# MCU_CTRL_MMR0_CFG0 register map
Vendor: Texas Instruments
Peripheral module from a debugger description file (folder am65x).
Registers are 32-bit, access per field, reset 0x0 unless marked. A register's access mark holds for its fields unless they carry their own. Offsets are as the file gives them; lines under a group give offsets from that group; [hi:lo] are bit positions; {n}, {i} and the like mark numbered series; 'fields as' and 'values as' point back to an identical list; <NAME> marks a mode.

## MCU_CTRL_MMR0_CFG0
0x00 CTRLMMR_MCU_PID ro reset 0x61800212 — Peripheral release details.
  [31:0] REV — TI internal data.
0x08 CTRLMMR_MCU_MMR_CFG1 ro reset 0x8000001F — Indicates the MMR configuration.
  [7:0] PARTITIONS — Indicates present partitions
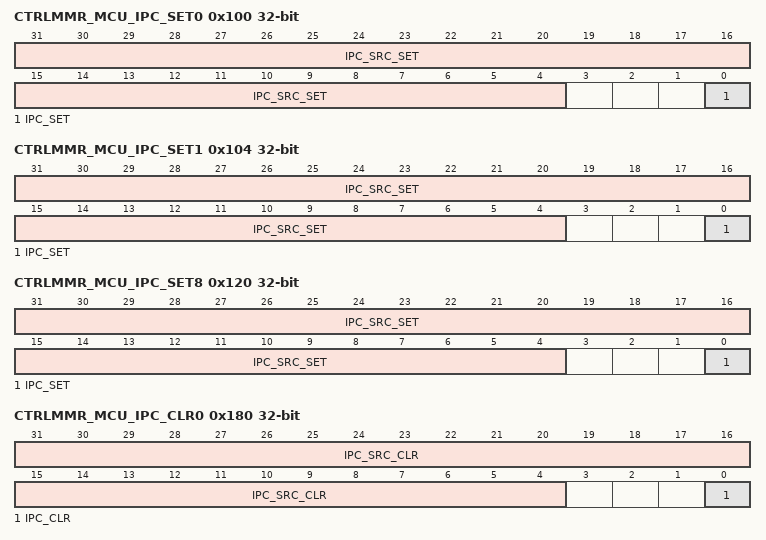
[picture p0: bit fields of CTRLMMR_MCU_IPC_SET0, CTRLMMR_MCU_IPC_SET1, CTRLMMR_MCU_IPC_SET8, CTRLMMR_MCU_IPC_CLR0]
0x100 CTRLMMR_MCU_IPC_SET0 access not given — Generate interprocessor communication interrupt to MCU R5 core0.
  [31:4] IPC_SRC_SET — Read returns current value (access W1TS)
  [0] IPC_SET — Read returns 0 (access W1TS)
0x104 CTRLMMR_MCU_IPC_SET1 access not given — Generate interprocessor communication interrupt to MCU R5 core1.
  fields as CTRLMMR_MCU_IPC_SET0
0x120 CTRLMMR_MCU_IPC_SET8 access not given — Generate interprocessor communication interrupt to DMSC.
  fields as CTRLMMR_MCU_IPC_SET0
0x180 CTRLMMR_MCU_IPC_CLR0 access not given — Acknowledge interprocessor communication interrupt to MCU R5 core0.
  [31:4] IPC_SRC_CLR — Read returns current value (access W1TC)
  [0] IPC_CLR — Read returns current value (access W1TC)
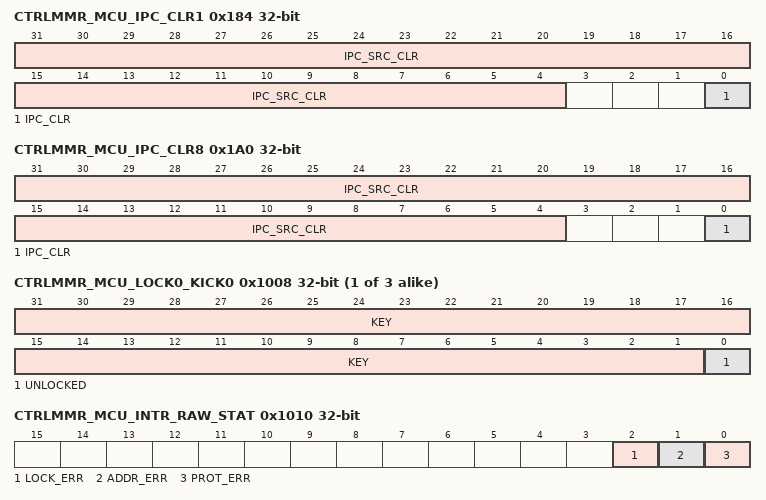
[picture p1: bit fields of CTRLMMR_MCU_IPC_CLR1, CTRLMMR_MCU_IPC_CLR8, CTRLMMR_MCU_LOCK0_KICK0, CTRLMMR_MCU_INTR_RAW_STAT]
0x184 CTRLMMR_MCU_IPC_CLR1 access not given — Acknowledge interprocessor communication interrupt to MCU R5 core1.
  fields as CTRLMMR_MCU_IPC_CLR0
0x1A0 CTRLMMR_MCU_IPC_CLR8 access not given — Acknowledge interprocessor communication interrupt to DMSC.
  fields as CTRLMMR_MCU_IPC_CLR0
0x200 CTRLMMR_MCU_MAC_ID0 ro reset not defined — MCU Ethernet MAC address lower 32-bits.
  [31:0] MACID_LO — 32 lsbs of MAC address
0x204 CTRLMMR_MCU_MAC_ID1 ro (reset mask 0xFFFF0000) — MCU Ethernet MAC address upper 16-bits.
  [15:0] MACID_HI — 16 msbs of MAC address
{0x1008+0x4000*i} CTRLMMR_MCU_LOCK{i}_KICK0 (i=0..2) — Lower 32-bits of Partition{i} write lock key. This register must be written with the designated key value followed by a write to CTRLMMR_MCU_LOCK{i}_KICK1 with its key value before write-protected Partition {i} registers can be written.
  [31:1] KEY rw — Write the kick0 unlock value followed by the kick1 unlock value to unlock the write-protected Partition{i} registers
  [0] UNLOCKED ro — Unlock status. When set indicates that the proper umlock sequence has been performed and the partition is unlocked for writing.
{0x100C+0x4000*i} CTRLMMR_MCU_LOCK{i}_KICK1 rw (i=0..2) — Upper 32-bits of Partition {i} write lock key. This register must be written with the designated key value after a write to CTRLMMR_MCU_LOCK{i}_KICK0 with its key value before write-protected Partition {i} registers can be written.
  [31:0] KEY — Write the kick1 unlock value after the kick0 unlock value to unlock the write-protected Partition{i} registers
0x1010 CTRLMMR_MCU_INTR_RAW_STAT access not given — Shows the interupt status (before enabling) and allows setting of the interrupt status (for test).
  [2] LOCK_ERR — Lock violation occurred (attempt to write a write-locked register with partition locked) (access W1TS)
  [1] ADDR_ERR — Address violation occurred (attempt to read or write an invalid register address) (access W1TS)
  [0] PROT_ERR — Protection violation occurred (attempt to to read or write a register with insufficient sucurity or privilege access rights) (access W1TS)
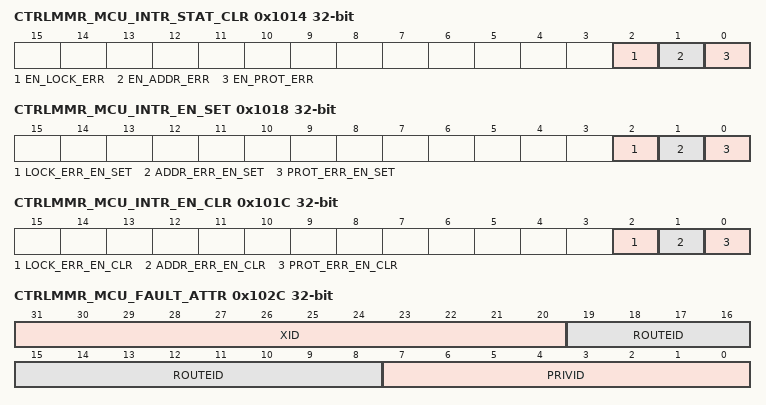
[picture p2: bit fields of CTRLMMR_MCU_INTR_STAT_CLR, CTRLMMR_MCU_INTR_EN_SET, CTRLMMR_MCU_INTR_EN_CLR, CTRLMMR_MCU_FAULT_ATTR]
0x1014 CTRLMMR_MCU_INTR_STAT_CLR access not given — Shows the enabled interrupt status and allows the interrupt to be cleared.
  [2] EN_LOCK_ERR — Enabled lock interrupt event status (access W1TC)
  [1] EN_ADDR_ERR — Enabled address interrupt event status (access W1TC)
  [0] EN_PROT_ERR — Enabled protection interrupt event status (access W1TC)
0x1018 CTRLMMR_MCU_INTR_EN_SET access not given — Allows interrupt enables to be set.
  [2] LOCK_ERR_EN_SET — Lock interrupt enable (access W1TS)
  [1] ADDR_ERR_EN_SET — Address interrupt enable (access W1TS)
  [0] PROT_ERR_EN_SET — Protection interrupt enable (access W1TS)
0x101C CTRLMMR_MCU_INTR_EN_CLR access not given — Allows interrupt enables to be cleared.
  [2] LOCK_ERR_EN_CLR — Lock interrupt disable (access W1TC)
  [1] ADDR_ERR_EN_CLR — Address interrupt disable (access W1TC)
  [0] PROT_ERR_EN_CLR — Protection interrupt disable (access W1TC)
0x1024 CTRLMMR_MCU_FAULT_ADDR ro — Indicates the address of the first transfer that caused a fault to occur.
  [31:0] ADDRESS — Address of the faulted access
0x1028 CTRLMMR_MCU_FAULT_TYPE ro — Indicates the access type of the first transfer that caused a fault to occur.
  [5:0] TYPE — Type of access which faulted 0h - No fault 1h - User execute access 2h - User write access 4h - User read access 8h - Supervisor execute access 10h - Supervisor write access 20h - Supervisor read access
0x102C CTRLMMR_MCU_FAULT_ATTR ro — Indicates the attributes of the first transfer that caused a fault to occur.
  [31:20] XID — Transaction ID
  [19:8] ROUTEID
  [7:0] PRIVID — Privilege ID
0x1030 CTRLMMR_MCU_FAULT_CLR access not given — Allows software to clear the current fault Clearing the current fault allows the CTRLMMR_MCU_FAULT_ADDR, CTRLMMR_MCU_FAULT_TYPE, and CTRLMMR_MCU_FAULT_ATTR registers to latch the attributes of the next fault that occurs. This does not affect the fault interrupt event itself. The interrupt must be cleared using the appropriate INTR_STATUS_CLR register bits.
  [0] CLEAR — Fault clear (access W1TC)
0x4030 CTRLMMR_MCU_MSMC_CFG reset 0x1 — Used to configure MSMC reset options.
  [0] DDR_32B_ADDR_EN rw — 32-bit DDR Addressing Enabled
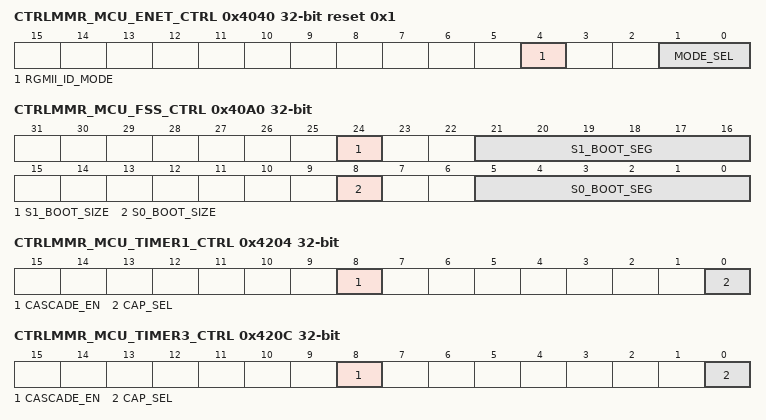
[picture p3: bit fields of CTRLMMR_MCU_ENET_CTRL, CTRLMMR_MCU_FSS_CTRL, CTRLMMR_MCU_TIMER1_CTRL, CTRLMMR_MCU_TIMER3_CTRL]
0x4040 CTRLMMR_MCU_ENET_CTRL reset 0x1 — Controls MCU Ethernet Port1 operation.
  [4] RGMII_ID_MODE rw — Port1 RGMII internal transmit delay selection
  [1:0] MODE_SEL rw — Selects ethernet switch Port1 interface 0h - GMII/MII (not supported) 1h - RMII 2h - RGMII 3h - SGMII (not supported)
0x4060 CTRLMMR_MCU_SPI1_CTRL — Controls if MCU_SPI1 is directly connected to SPI3 in the MAIN Domain (default) or if MCU_SPI1 and SPI3 are independently pinned out.
  [0] SPI1_LINKDIS rw — Disables direct connection of MCU_SPI1 to SPI3 0h - MCU_SPI1 is tied as a slave to SPI3. MCU_SPI1 CLK, DATA1 and CS0 are driven from SPI3, DATA OUT drives SPI3 DATA0 1h - MCU_SPI1 is NOT tied as a slave to SPI3. MCU_SPI1 CLK, DATA0, DATA1 and CS[3:0] are controlled through their respective MCU_SPI1 pins and SPI3 CLK, DATA0, DATA1, and CS[3:0] are controlled through their respective SPI3 pins.
0x40A0 CTRLMMR_MCU_FSS_CTRL — Controls Flash boot region size and placement.
  [24] S1_BOOT_SIZE rw — Selects the size of the boot block to be used for the S1 (OSPI1) flash interface
  [21:16] S1_BOOT_SEG rw — Selects the boot block to be used for the S1 (OSPI1) flash interface. If the s1_boot_size is 128 MB then only bits [4:0] of this field are used. Care must be taken to account for the address translation as to not fall off or wrap the address of the flash. (e.g. if both ECC and authentication are enabled for 64 MB boot, the highest valid block number is is 49, as sector 50 is only .2M Bytes in size.)
  [8] S0_BOOT_SIZE rw — Selects the size of the boot block to be used for the S0 (OSPI0 or HyperBus) flash interface
  [5:0] S0_BOOT_SEG rw — Selects the boot block to be used for the S0 (OSPI0 or HyperBus) flash interface. If the s0_boot_size is 128 MB then only bits [4:0] of this field are used. Care must be taken to account for the address translation as to not fall off or wrap the address of the flash. (e.g. if both ECC and authentication are enabled for 64 MB boot, the highest valid block number is is 49, as sector 50 is only .2M Bytes in size.)
0x40B0 CTRLMMR_MCU_ADC0_CTRL — Controls operation of MCU ADC0.
  [4:0] TRIG_SEL rw — Selects the source of the ADC hardware event trigger 0h - MCU_ADC0_EXT_TRIGGER pin 1h - MCU_ADC1_EXT_TRIGGER pin 2h - eHRPWM SOCA event 3h - eHRPWM SOCB event 4h - MCU Timer0 PWM output 5h - MCU Timer1 PWM output 6h - MCU Timer2 PWM output 7h - MCU Timer3 PWM output 8h - Timer0 PWM output 9h - Timer1 PWM output Ah - Timer2 PWM output Bh - Timer3 PWM output Ch - Timer4 PWM output Dh - Timer5 PWM output Eh - Timer6 PWM output Fh - Timer7 PWM output 10h - Timer8 PWM output 11h - Timer9 PWM output 12h - Timer10 PWM output 13h - Timer11 PWM output 14h - ICSS-G0 IEP0 CMP15 event 15h - ICSS-G0 IEP1 CMP15 event 16h - ICSS-G1 IEP0 CMP15 event 17h - ICSS-G1 IEP1 CMP15 event 18h - ICSS-G2 IEP0 CMP15 event 19h - ICSS-G2 IEP1 CMP15 event 1Ah - Reserved (tied 1'b0) 1Bh - Reserved (tied 1'b0) 1Ch - Reserved (tied 1'b0) 1Dh - Reserved (tied 1'b0) 1Eh - Reserved (tied 1'b0) 1Fh - Reserved (tied 1'b0)
0x40B4 CTRLMMR_MCU_ADC1_CTRL reset 0x1 — Controls operation of MCU ADC1.
  fields as CTRLMMR_MCU_ADC0_CTRL
0x4200 CTRLMMR_MCU_TIMER0_CTRL — Controls MCU Timer0 operation.
  [0] CAP_SEL rw — Selects the MCU_TIMERIO input pin for capture input signal. This control is only used when TIMER0 is configured for capture operation.
0x4204 CTRLMMR_MCU_TIMER1_CTRL — Controls MCU Timer1 operation.
  [8] CASCADE_EN rw — When set, enables cascading of MCU_TIMER1 to MCU_TIMER0Timer cascading is shown on
  [0] CAP_SEL rw — Selects the MCU_TIMERIO input pin for capture input signal. This control is only used when TIMER1 is configured for capture operation.
0x4208 CTRLMMR_MCU_TIMER2_CTRL — Controls MCU Timer2 operation.
  [0] CAP_SEL rw — Selects the MCU_TIMERIO input pin for capture input signal. This control is only used when TIMER2 is configured for capture operation.
0x420C CTRLMMR_MCU_TIMER3_CTRL — Controls MCU Timer3 operation.
  [8] CASCADE_EN rw — When set, enables cascading of MCU_TIMER3 to MCU_TIMER2Timer cascading is shown on
  [0] CAP_SEL rw — Selects the MCU_TIMERIO input pin for capture input signal. This control is only used when TIMER3 is configured for capture operation.
0x4280 CTRLMMR_MCU_TIMERIO0_CTRL — Controls MCU TimerIO muxing.
  [1:0] OUT_SEL rw — Selects the source of the MCU_TIMERIO0 output. 0h - MCU_TIMERIO0 is driven by MCU_TIMER0 output 1h - MCU_TIMERIO0 is driven by MCU_TIMER1 output 2h - MCU_TIMERIO0 is driven by MCU_TIMER2 output 3h - MCU_TIMERIO0 is driven by MCU_TIMER3 output
0x4284 CTRLMMR_MCU_TIMERIO1_CTRL — Controls MCU TimerIO muxing.
  [1:0] OUT_SEL rw — Selects the source of the MCU_TIMERIO1 output. 0h - MCU_TIMERIO1 is driven by MCU_TIMER0 output 1h - MCU_TIMERIO1 is driven by MCU_TIMER1 output 2h - MCU_TIMERIO1 is driven by MCU_TIMER2 output 3h - MCU_TIMERIO1 is driven by MCU_TIMER3 output
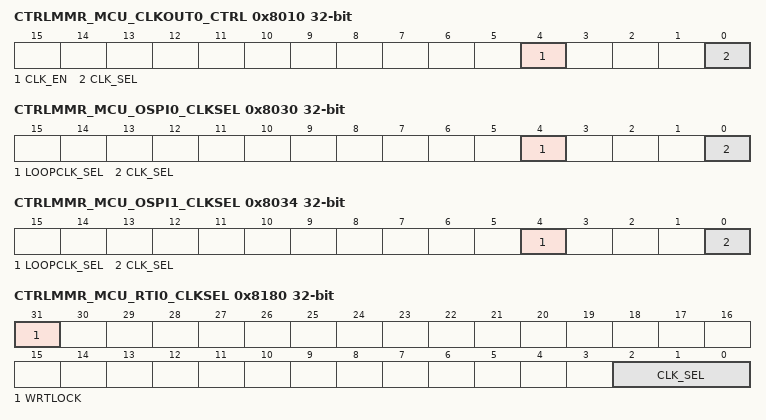
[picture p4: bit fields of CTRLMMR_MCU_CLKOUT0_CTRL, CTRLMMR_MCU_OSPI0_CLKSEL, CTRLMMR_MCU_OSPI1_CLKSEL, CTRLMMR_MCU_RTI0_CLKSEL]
0x8010 CTRLMMR_MCU_CLKOUT0_CTRL — Enables and selects clock source of CPSW MCU_CLKOUT0 pin.
  [4] CLK_EN rw — When set, enables MCU_CLKOUT0 output
  [0] CLK_SEL rw — Selects MCU_CLKOUT0 clock source
0x8018 CTRLMMR_MCU_EFUSE_CLKSEL — Selects the functional clock source for the MCU domain eFuse Controller.
  [0] CLK_SEL rw — Selects the clock source 0h - EFUSE_CLK (HFOSC0_CLKOUT or CLK_12M_RC) 1h - MCU_SYSCLK0 / 8
0x8020 CTRLMMR_MCU_MCAN0_CLKSEL — Controls the functional clock source for MCU_MCAN0.
  [1:0] CLK_SEL rw — MCU_MCAN MCAN_CLK selection
0x8024 CTRLMMR_MCU_MCAN1_CLKSEL — Controls the functional clock source for MCU_MCAN1.
  [1:0] CLK_SEL rw — MCU_MCAN MCAN_CLK selection
0x8030 CTRLMMR_MCU_OSPI0_CLKSEL — Controls the OSPI loopback clock source.
  [4] LOOPCLK_SEL rw — OBSPI0 Loopback clock source
  [0] CLK_SEL rw — OSPI0 reference clock selection
0x8034 CTRLMMR_MCU_OSPI1_CLKSEL — Controls the OSPI loopback clock source.
  [4] LOOPCLK_SEL rw — OBSPI1 Loopback clock source
  [0] CLK_SEL rw — OSPI1 reference clock selection
0x8040 CTRLMMR_MCU_ADC0_CLKSEL — Controls the functional clock source for the MCU_ADC0.
  [1:0] CLK_SEL rw — Selects the sampling clock source for ADC0 0h - HFOSC0_CLKOUT 1h - MCUHSDIV_CLKOUT1 2h - CPSWHSDIV_CLKOUT3 3h - MCU_EXT_REFCLK0
0x8044 CTRLMMR_MCU_ADC1_CLKSEL — Controls the functional clock source for the MCU_ADC1.
  [1:0] CLK_SEL rw — Selects the sampling clock source for ADC1 0h - HFOSC0_CLKOUT 1h - MCUHSDIV_CLKOUT1 2h - CPSWHSDIV_CLKOUT3 3h - MCU_EXT_REFCLK0
0x8050 CTRLMMR_MCU_ENET_CLKSEL — Controls selectable clock sources for the MCU Ethernet Port1.
  [0] RMII_CLK_SEL rw — Selects the rmii clock (rmii_mhz_50_clk) source. This defaults to the internal 50 MHz clock source for proper clockstop operation
0x8080 CTRLMMR_MCU_R5_CORE0_CLKSEL — MCU Core 0 functional clock selection control.
  [0] CLK_SEL rw — Selects the Core 0 functional clock and mcu/interface clock ratio
0x8084 CTRLMMR_MCU_R5_CORE1_CLKSEL — MCU Core 1 functional clock selection control.
  [0] CLK_SEL rw — Selects the Core 1 functional clock and mcu/interface clock ratio
{0x8100+4i} CTRLMMR_MCU_TIMER{i}_CLKSEL (i=0..3) — MCU Timer{i} functional clock selection control.
  [2:0] CLK_SEL rw — Timer functional clock input select mux control 0h - HFOSC0_CLKOUT 1h - MCU_SYSCLK0 / 2 2h - CLK_12M_RC 3h - MCU_CPSW_PLL_CLKOUT 4h - MCU_EXT_REFCLK0 5h - LFOSC_CLKOUT 6h - CPSW_GENF0 7h - CLK_32K_RC
0x8180 CTRLMMR_MCU_RTI0_CLKSEL — MCU RTI0 functional clock selection control.
  [31] WRTLOCK rw — When set, locks further writes to CTRLMMR_MCU_RTI0_CLKSEL until the next module reset
  [2:0] CLK_SEL rw — RTI functional clock input select mux control. The msb is unused but should be written as 1'b0 to maintain compatibility with future devices. 0h - HFOSC0_CLKOUT 1h - LFOSC_CLKOUT 2h - CLK_12M_RC 3h - CLK_32K_RC
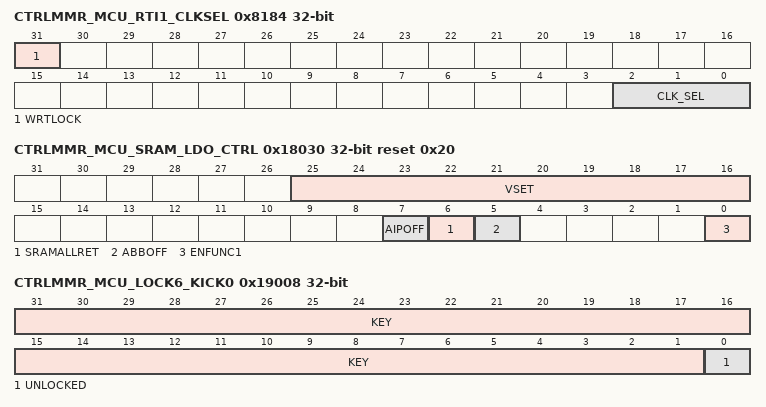
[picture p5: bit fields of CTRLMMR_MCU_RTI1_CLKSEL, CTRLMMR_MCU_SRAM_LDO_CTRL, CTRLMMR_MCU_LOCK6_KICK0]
0x8184 CTRLMMR_MCU_RTI1_CLKSEL — MCU RTI1 functional clock selection control.
  [31] WRTLOCK rw — When set, locks further writes to CTRLMMR_MCU_RTI1_CLKSEL until the next module reset
  [2:0] CLK_SEL rw — RTI functional clock input select mux control. The msb is unused but should be written as 1'b0 to maintain compatibility with future devices. 0h - HFOSC0_CLKOUT 1h - LFOSC_CLKOUT 2h - CLK_12M_RC 3h - CLK_32K_RC
0x81C0 CTRLMMR_MCU_USART_CLKSEL — Controls the functional clock source for MCU_USART0.
  [0] CLK_SEL rw — MCU_USART0 FCLK selection
0x18030 CTRLMMR_MCU_SRAM_LDO_CTRL reset 0x20 (reset mask 0xFC00FFFF) — Controls operation of the MCU VD SRAM LDO module.
  [25:16] VSET rw — LDO trim bits
  [7] AIPOFF rw — When set, disables the VSLDO and enabbles IDDQ test mode
  [6] SRAMALLRET rw — When set, places the VSLDO in retention mode
  [5] ABBOFF rw — When set, shorts the VNWA voltage to VDDAR
  [0] ENFUNC1 rw — Control the LDO loop dynamics. Setting enfunc1 decreases loop gain by 6dB.
0x19008 CTRLMMR_MCU_LOCK6_KICK0 — Lower 32-bits of Partition6 write lock key. This register must be written with the designated key value followed by a write to CTRLMMR_MCU_LOCK6_KICK1 with its key value before write-protected Partition 6 registers can be written.
  [31:1] KEY rw — Write the kick0 unlock value followed by the kick1 unlock value to unlock the write-protected Partition6 registers
  [0] UNLOCKED ro — Unlock status. When set indicates that the proper umlock sequence has been performed and the partition is unlocked for writing.
0x1900C CTRLMMR_MCU_LOCK6_KICK1 rw — Upper 32-bits of Partition 6 write lock key. This register must be written with the designated key value after a write to CTRLMMR_MCU_LOCK6_KICK0 with its key value before write-protected Partition 6 registers can be written.
  [31:0] KEY — Write the kick1 unlock value after the kick0 unlock value to unlock the write-protected Partition6 registers
